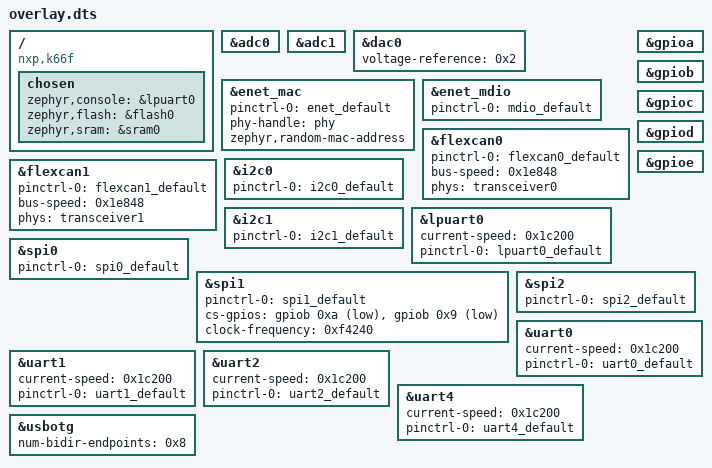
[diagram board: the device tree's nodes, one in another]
/ {
	compatible = "nxp,k66f", "nxp,k6x", "nxp,mk66f18";
	chosen {
		zephyr,console = &lpuart0;
		zephyr,flash = &flash0;
		zephyr,sram = &sram0;
	};
};
&adc0{
	status = "okay";
};
&adc1{
	status = "okay";
};
&dac0{
	voltage-reference = < 0x2 >;
	status = "okay";
};
&enet_mac{
	status = "okay";
	pinctrl-0 = < &enet_default >;
	pinctrl-names = "default";
	phy-handle = < &phy >;
	zephyr,random-mac-address;
};
&enet_mdio{
	status = "okay";
	pinctrl-0 = < &mdio_default >;
	pinctrl-names = "default";
};
&flexcan0{
	status = "okay";
	pinctrl-0 = < &flexcan0_default >;
	pinctrl-names = "default";
	bus-speed = < 0x1e848 >;
	phys = < &transceiver0 >;
};
&flexcan1{
	status = "okay";
	pinctrl-0 = < &flexcan1_default >;
	pinctrl-names = "default";
	bus-speed = < 0x1e848 >;
	phys = < &transceiver1 >;
};
&gpioa{
	status = "okay";
};
&gpiob{
	status = "okay";
};
&gpioc{
	status = "okay";
};
&gpiod{
	status = "okay";
};
&gpioe{
	status = "okay";
};
&i2c0{
	status = "okay";
	pinctrl-0 = < &i2c0_default >;
	pinctrl-names = "default";
};
&i2c1{
	status = "okay";
	pinctrl-0 = < &i2c1_default >;
	pinctrl-names = "default";
};
&lpuart0{
	status = "okay";
	current-speed = < 0x1c200 >;
	pinctrl-0 = < &lpuart0_default >;
	pinctrl-names = "default";
};
&spi0{
	status = "okay";
	pinctrl-0 = < &spi0_default >;
	pinctrl-names = "default";
};
&spi1{
	status = "okay";
	pinctrl-0 = < &spi1_default >;
	pinctrl-names = "default";
	cs-gpios = < &gpiob 0xa 0x1 >, < &gpiob 0x9 0x1 >;
	clock-frequency = < 0xf4240 >;
};
&spi2{
	status = "okay";
	pinctrl-0 = < &spi2_default >;
	pinctrl-names = "default";
};
&uart0{
	status = "okay";
	current-speed = < 0x1c200 >;
	pinctrl-0 = < &uart0_default >;
	pinctrl-names = "default";
};
&uart1{
	status = "okay";
	current-speed = < 0x1c200 >;
	pinctrl-0 = < &uart1_default >;
	pinctrl-names = "default";
};
&uart2{
	status = "okay";
	current-speed = < 0x1c200 >;
	pinctrl-0 = < &uart2_default >;
	pinctrl-names = "default";
};
&uart4{
	status = "okay";
	current-speed = < 0x1c200 >;
	pinctrl-0 = < &uart4_default >;
	pinctrl-names = "default";
};
&usbotg{
	num-bidir-endpoints = < 0x8 >;
	status = "okay";
};
